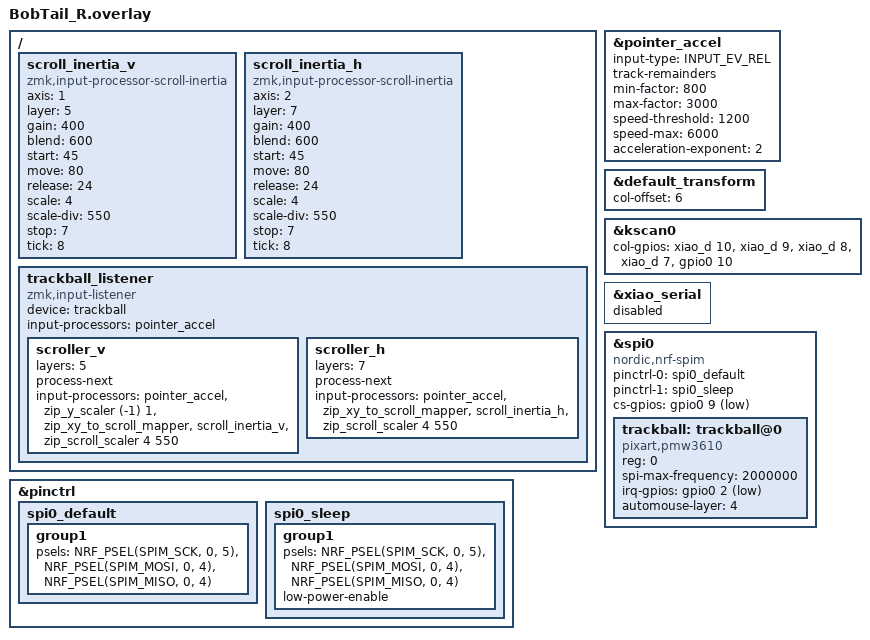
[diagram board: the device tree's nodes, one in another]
#include "BobTail.dtsi"
#include <input/processors.dtsi>
#include <behaviors/input_gestures_accel.dtsi>

/ {
    scroll_inertia_v: scroll_inertia_v {
        compatible = "zmk,input-processor-scroll-inertia";
        #input-processor-cells = <0>;

        axis = <1>;
        layer = <5>;

        gain = <400>;
        blend = <600>;

        start = <45>;
        move = <80>;
        release = <24>;

        scale = <4>;
        scale-div = <550>;

        stop = <7>;
        tick = <8>;
    };

    scroll_inertia_h: scroll_inertia_h {
        compatible = "zmk,input-processor-scroll-inertia";
        #input-processor-cells = <0>;

        axis = <2>;
        layer = <7>;

        gain = <400>;
        blend = <600>;

        start = <45>;
        move = <80>;
        release = <24>;

        scale = <4>;
        scale-div = <550>;

        stop = <7>;
        tick = <8>;
    };

    trackball_listener: trackball_listener {
        compatible = "zmk,input-listener";
        device = <&trackball>;

        /*
         * 通常のカーソル移動
         */
        input-processors = <
            &pointer_accel
        >;

        /*
         * Layer 5
         * 縦スクロール
         *
         * 加速度 → スクロール変換 → 慣性
         */
        scroller_v {
            layers = <5>;
            process-next;

            input-processors = <
                &pointer_accel
                &zip_y_scaler (-1) 1
                &zip_xy_to_scroll_mapper
                &scroll_inertia_v
                &zip_scroll_scaler 4 550
            >;
        };

        /*
         * Layer 7
         * 横スクロール
         *
         * 加速度 → スクロール変換 → 慣性
         */
        scroller_h {
            layers = <7>;
            process-next;

            input-processors = <
                &pointer_accel
                &zip_xy_to_scroll_mapper
                &scroll_inertia_h
                &zip_scroll_scaler 4 550
            >;
        };
    };
};

/*
 * ポインター加速度
 *
 * 通常カーソル:
 *   低速  0.8倍
 *   高速  最大3倍
 *
 * スクロールにも同じ加速度を実験的に適用
 */
&pointer_accel {
    input-type = <INPUT_EV_REL>;
    track-remainders;

    min-factor = <800>;
    max-factor = <3000>;

    speed-threshold = <1200>;
    speed-max = <6000>;

    acceleration-exponent = <2>;
};

&default_transform {
    col-offset = <6>;
};

&kscan0 {
    col-gpios
        = <&xiao_d 10 GPIO_ACTIVE_HIGH>
        , <&xiao_d 9 GPIO_ACTIVE_HIGH>
        , <&xiao_d 8 GPIO_ACTIVE_HIGH>
        , <&xiao_d 7 GPIO_ACTIVE_HIGH>
        , <&gpio0 10 GPIO_ACTIVE_HIGH>
        ;
};

&pinctrl {
    spi0_default: spi0_default {
        group1 {
            psels = <NRF_PSEL(SPIM_SCK, 0, 5)>,
                <NRF_PSEL(SPIM_MOSI, 0, 4)>,
                <NRF_PSEL(SPIM_MISO, 0, 4)>;
        };
    };

    spi0_sleep: spi0_sleep {
        group1 {
            psels = <NRF_PSEL(SPIM_SCK, 0, 5)>,
                <NRF_PSEL(SPIM_MOSI, 0, 4)>,
                <NRF_PSEL(SPIM_MISO, 0, 4)>;
            low-power-enable;
        };
    };
};

&xiao_serial {
    status = "disabled";
};

&spi0 {
    status = "okay";
    compatible = "nordic,nrf-spim";
    pinctrl-0 = <&spi0_default>;
    pinctrl-1 = <&spi0_sleep>;
    pinctrl-names = "default", "sleep";
    cs-gpios = <&gpio0 9 GPIO_ACTIVE_LOW>;

    trackball: trackball@0 {
        status = "okay";
        compatible = "pixart,pmw3610";
        reg = <0>;
        spi-max-frequency = <2000000>;
        irq-gpios = <&gpio0 2 (GPIO_ACTIVE_LOW | GPIO_PULL_UP)>;
        automouse-layer = <4>;
    };
};
